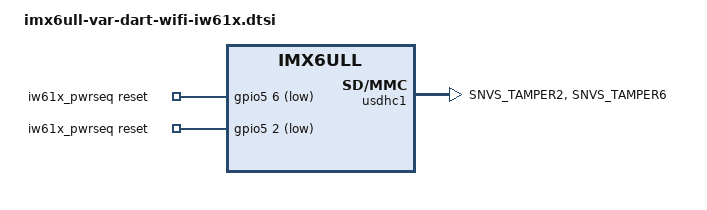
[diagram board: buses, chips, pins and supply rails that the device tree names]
/*
 * Copyright 2024 Variscite Ltd. - https://www.variscite.com
 *
 * This program is free software; you can redistribute it and/or modify
 * it under the terms of the GNU General Public License version 2 as
 * published by the Free Software Foundation.
 */

#include "imx6ul-imx6ull-var-dart-wifi-brcm.dtsi"

/ {
	iw61x_pwrseq: iw61x_pwrseq {
		compatible = "mmc-pwrseq-simple";
		post-power-on-delay-ms = <100>;
		power-off-delay-us = <10000>;
		reset-gpios = <&gpio5 6 GPIO_ACTIVE_LOW>,	/* WIFI_RESET */
			      <&gpio5 2 GPIO_ACTIVE_LOW>;	/* WIFI_PWR_EN */
		status = "okay";
	};
};

&iomuxc {
	pinctrl_wifi: wifigrp {
		fsl,pins = <
			MX6ULL_PAD_SNVS_TAMPER2__GPIO5_IO02	0x1b0b0
			MX6ULL_PAD_SNVS_TAMPER6__GPIO5_IO06	0x1b0b0
		>;
	};
};

&usdhc1 {
	pinctrl-0 = <&pinctrl_usdhc1>, <&pinctrl_32k_clk>, <&pinctrl_wifi>;
	pinctrl-1 = <&pinctrl_usdhc1_100mhz>, <&pinctrl_32k_clk>, <&pinctrl_wifi>;
	pinctrl-2 = <&pinctrl_usdhc1_200mhz>, <&pinctrl_32k_clk>, <&pinctrl_wifi>;
	mmc-pwrseq = <&iw61x_pwrseq>;

	/delete-node/ bcrmf@1;
};
